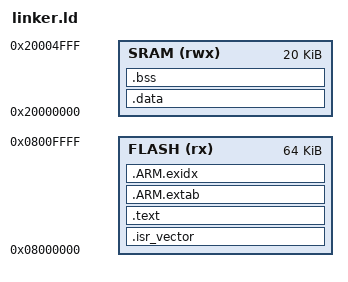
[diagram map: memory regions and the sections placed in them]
ENTRY(Reset_Handler)

MEMORY
{
    FLASH (rx)  : ORIGIN = 0x08000000, LENGTH = 64K
    SRAM  (rwx) : ORIGIN = 0x20000000, LENGTH = 20K
}

_estack = ORIGIN(SRAM) + LENGTH(SRAM);

SECTIONS
{
    .isr_vector :
    {
        . = ALIGN(4);
        KEEP(*(.isr_vector))
        . = ALIGN(4);
    } > FLASH

    .text :
    {
        . = ALIGN(4);
        *(.text*)
        *(.rodata*)
        *(.glue_7)
        *(.glue_7t)
        KEEP(*(.init))
        KEEP(*(.fini))
        . = ALIGN(4);
        _etext = .;
    } > FLASH

    .ARM.extab :
    {
        *(.ARM.extab*)
    } > FLASH

    .ARM.exidx :
    {
        __exidx_start = .;
        *(.ARM.exidx*)
        __exidx_end = .;
    } > FLASH

    _sidata = LOADADDR(.data);

    .data : AT(_etext)
    {
        . = ALIGN(4);
        _sdata = .;
        *(.data*)
        . = ALIGN(4);
        _edata = .;
    } > SRAM

    .bss :
    {
        . = ALIGN(4);
        _sbss = .;
        *(.bss*)
        *(COMMON)
        . = ALIGN(4);
        _ebss = .;
    } > SRAM

    . = ALIGN(4);
    _end = .;
}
